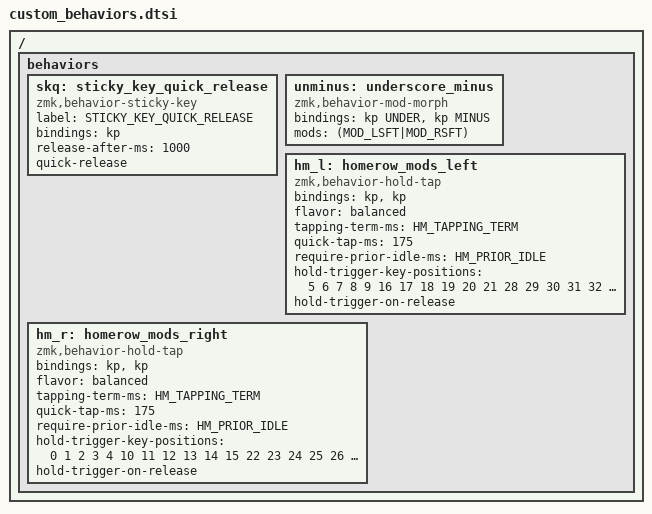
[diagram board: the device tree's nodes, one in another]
#define HM_TAPPING_TERM 300
#define HM_PRIOR_IDLE 150

/ {

    behaviors {

        // Sticky Key quick release
        skq: sticky_key_quick_release {
          compatible = "zmk,behavior-sticky-key";
          label = "STICKY_KEY_QUICK_RELEASE";
          #binding-cells = <1>;
          bindings = <&kp>;
          release-after-ms = <1000>;
          quick-release;
        };


        // Reversed minus (underscore by default and minus with shift)
        unminus: underscore_minus {
            compatible = "zmk,behavior-mod-morph";
            #binding-cells = <0>;
            bindings = <&kp UNDER>, <&kp MINUS>;
            mods = <(MOD_LSFT|MOD_RSFT)>;
        };

        // Positional Homerow mods
        // Homerow mods that prevent accidental activations when rolling keys,
        // such as when typing `st` or `ne` on colemak-dh layouts or `as` on
        // qwerty.
        //
        // Works by only allowing a mod to activate within tapping-term if
        // it's on the opposite side of the keyboard or on the same side thumb
        // keys.

        // Further optimization using urob's timerless homerow mods method:
        // https://github.com/urob/zmk-config#timeless-homerow-mods
        hm_l: homerow_mods_left {
            compatible = "zmk,behavior-hold-tap";
            #binding-cells = <2>;
            bindings = <&kp>,  <&kp>;

            flavor = "balanced";
            tapping-term-ms = <HM_TAPPING_TERM>;
            quick-tap-ms = <175>;                // repeat on tap-into-hold
            require-prior-idle-ms = <HM_PRIOR_IDLE>;

            hold-trigger-key-positions = <5 6 7 8 9 16 17 18 19 20 21 28 29 30 31 32 33 40 41 42 43 44 45 55 56 57 58 59 60 61 62 63 72 73 74 75 76 77 78 79>;
            hold-trigger-on-release;
        };

        hm_r: homerow_mods_right {
            compatible = "zmk,behavior-hold-tap";
            #binding-cells = <2>;
            bindings = <&kp>, <&kp>;

            flavor = "balanced";
            tapping-term-ms = <HM_TAPPING_TERM>;
            quick-tap-ms = <175>;
            require-prior-idle-ms = <HM_PRIOR_IDLE>;
            
            hold-trigger-key-positions = <0 1 2 3 4 10 11 12 13 14 15 22 23 24 25 26 27 34 35 36 37 38 39 46 47 48 49 50 51 52 53 54 64 65 66 67 68 69 70 71>;
            hold-trigger-on-release;
        };

    };
};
